# ADC register map
Vendor: Texas Instruments
Peripheral module from a debugger description file (folder ucd3138128).
Registers are 32-bit, access not given, no defined reset value unless marked. A register's access mark holds for its fields unless they carry their own. Offsets are as the file gives them; lines under a group give offsets from that group; [hi:lo] are bit positions; {n}, {i} and the like mark numbered series; 'fields as' and 'values as' point back to an identical list; <NAME> marks a mode.

## ADC
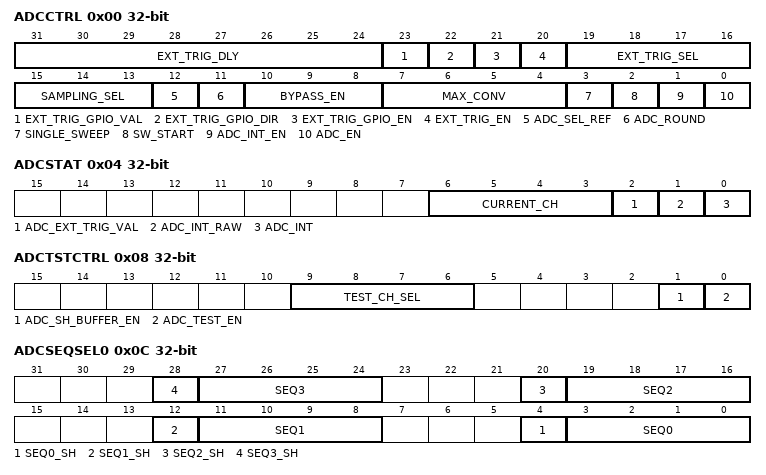
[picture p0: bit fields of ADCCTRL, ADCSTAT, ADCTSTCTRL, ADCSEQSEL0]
0x00 ADCCTRL rw — ADC Control Register
  [31:24] EXT_TRIG_DLY — External ADC Trigger Delay
  [23] EXT_TRIG_GPIO_VAL — ADC External Trigger GPIO Value
  [22] EXT_TRIG_GPIO_DIR — ADC External Trigger GPIO Direction
  [21] EXT_TRIG_GPIO_EN — ADC External Trigger GPIO Enable
  [20] EXT_TRIG_EN — External ADC Trigger Enable
  [19:16] EXT_TRIG_SEL — External ADC Trigger Select
  [15:13] SAMPLING_SEL — Sampling Select
  [12] ADC_SEL_REF — ADC Reference Select
  [11] ADC_ROUND — ADC Rounding Enable
  [10:8] BYPASS_EN — Dual Sample and Hold Bypass
  [7:4] MAX_CONV — Maximum Number of Conversions
  [3] SINGLE_SWEEP — Single Loop Sweep Select
  [2] SW_START — Software start of conversion
  [1] ADC_INT_EN — ADC End of Conversion Interrupt
  [0] ADC_EN — ADC Enable
0x04 ADCSTAT — ADC Status Register
  [6:3] CURRENT_CH ro — Current Channel
  [2] ADC_EXT_TRIG_VAL ro — ADC External Trigger Pin Value
  [1] ADC_INT_RAW ro — End of Conversion Status, Raw
  [0] ADC_INT ro — Latched Interrupt Status
0x08 ADCTSTCTRL — ADC Test Control Register
  [9:6] TEST_CH_SEL rw — Test channel select
  [1] ADC_SH_BUFFER_EN rw — ADC Sample/Hold Buffer override enable
  [0] ADC_TEST_EN rw — ADC test enable
0x0C ADCSEQSEL0 — ADC Sequencer Select Register 0
  [8n+4] SEQ{n}_SH rw (n=0..3) — Dual channel sequence select
  [8n+3:8n] SEQ{n} rw (n=0..3) — Conversion #{n} channel
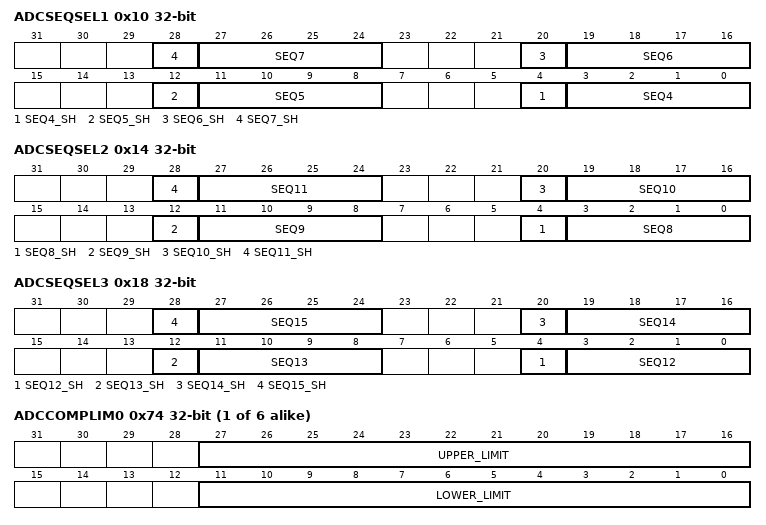
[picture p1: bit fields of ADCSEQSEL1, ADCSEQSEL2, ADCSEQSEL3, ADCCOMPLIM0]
0x10 ADCSEQSEL1 — ADC Sequencer Select Register 1
  [8n-28] SEQ{n}_SH rw (n=4..7) — Dual channel sequence select
  [8n-29:8n-32] SEQ{n} rw (n=4..7) — Conversion #{n} channel
0x14 ADCSEQSEL2 — ADC Sequencer Select Register 2
  [8n-60] SEQ{n}_SH rw (n=8..11) — Dual channel sequence select
  [8n-61:8n-64] SEQ{n} rw (n=8..11) — Conversion #{n} channel
0x18 ADCSEQSEL3 — ADC Sequencer Select Register 3
  [8n-92] SEQ{n}_SH rw (n=12..15) — Dual channel sequence select
  [8n-93:8n-96] SEQ{n} rw (n=12..15) — Conversion #{n} channel
{0x1C+4i} ADCRESULT{i} (i=0..15) — ADC Conversion Result 0:15
  [11:0] RESULT ro — Conversion result
{0x5C+4i} ADCAVGRESULT{i} (i=0..5) — ADC Averaged Conversion Result 0:5
  [11:0] RESULT ro — Conversion result
{0x74+4i} ADCCOMPLIM{i} (i=0..5) — ADC Digital Compare Limits Register 0:5
  [27:16] UPPER_LIMIT rw, [11:0] LOWER_LIMIT rw
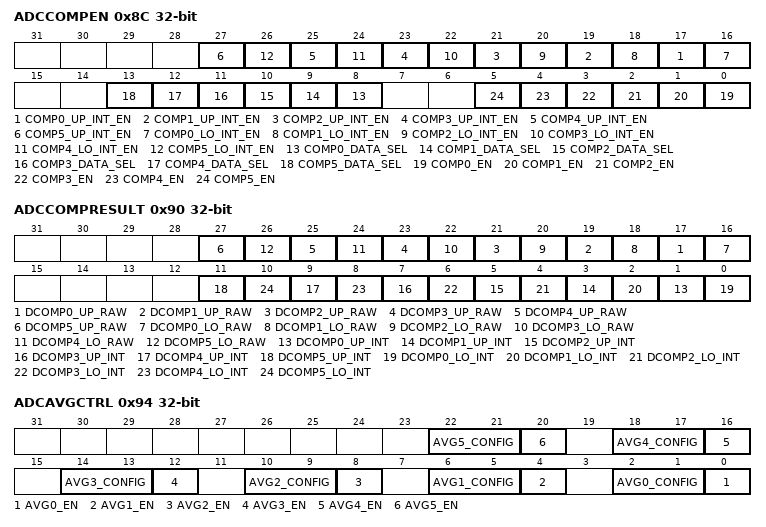
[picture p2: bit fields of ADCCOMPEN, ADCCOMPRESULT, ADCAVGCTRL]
0x8C ADCCOMPEN — ADC Digital Compare Enable Register
  [2n+17] COMP{n}_UP_INT_EN rw (n=0..5) — Comparator {n} Upper Interrupt Enable
  [2n+16] COMP{n}_LO_INT_EN rw (n=0..5) — Comparator {n} Lower Interrupt Enable
  [n+8] COMP{n}_DATA_SEL rw (n=0..5) — Comparator {n} Data Select
  [n] COMP{n}_EN rw (n=0..5) — Digital comparator {n} enable
0x90 ADCCOMPRESULT — ADC Digital Compare Result Register
  [2n+17] DCOMP{n}_UP_RAW ro (n=0..5) — Comparator {n} Upper Limit Raw Result
  [2n+16] DCOMP{n}_LO_RAW ro (n=0..5) — Comparator {n} Lower Limit Raw Result
  [2n+1] DCOMP{n}_UP_INT ro (n=0..5) — Comparator 5 Upper Limit Latch Result
  [2n] DCOMP{n}_LO_INT ro (n=0..5) — Comparator 5 Lower Limit Latch Result
0x94 ADCAVGCTRL — ADC Averaging Control Register
  [4n+2:4n+1] AVG{n}_CONFIG rw (n=0..5) — Averaging Module {n} Configuration
  [4n] AVG{n}_EN rw (n=0..5) — Averaging Module {n} Enable
